VERSION "roxy-can sample database"

NS_ :

BU_: EngineECU ChassisECU Dashboard

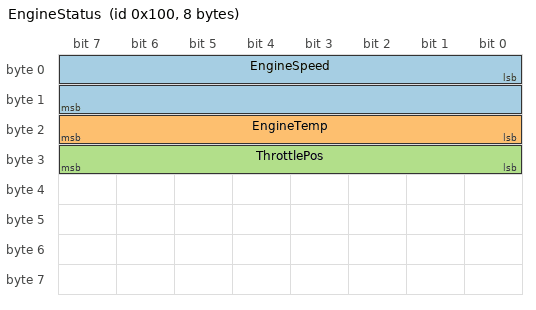
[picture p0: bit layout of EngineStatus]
BO_ 256 EngineStatus: 8 EngineECU
 SG_ EngineSpeed : 0|16@1+ (0.25,0) [0|8000] "rpm" Dashboard,ChassisECU
 SG_ EngineTemp : 16|8@1+ (1,-40) [-40|215] "degC" Dashboard
 SG_ ThrottlePos : 24|8@1+ (0.4,0) [0|100] "%" ChassisECU

BO_ 512 VehicleState: 8 ChassisECU
 SG_ VehicleSpeed : 0|16@1+ (0.01,0) [0|300] "km/h" Dashboard,EngineECU
 SG_ GearPosition : 16|3@1+ (1,0) [0|6] "" Dashboard

BO_ 800 BrakeInfo: 8 ChassisECU
 SG_ BrakePressure : 0|16@1+ (0.1,0) [0|100] "bar" Dashboard,EngineECU
